# adc14 register map
Vendor: Texas Instruments
Peripheral module from a debugger description file (folder MSP432).
Registers are 32-bit, read-write, no defined reset value unless marked. A register's access mark holds for its fields unless they carry their own. Offsets are as the file gives them; lines under a group give offsets from that group; [hi:lo] are bit positions; {n}, {i} and the like mark numbered series; 'fields as' and 'values as' point back to an identical list; <NAME> marks a mode.

## ADC14
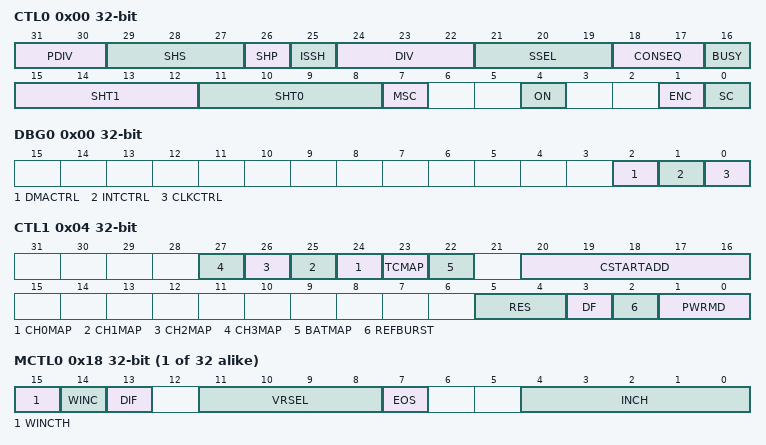
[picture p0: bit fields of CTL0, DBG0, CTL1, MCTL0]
0x00 CTL0 — Control 0 Register
  [31:30] PDIV — ADC14 predivider
    0=PDIV__0 (Predivide by 1); 1=PDIV__1 (Predivide by 4); 2=PDIV__2 (Predivide by 32); 3=PDIV__3 (Predivide by 64)
  [29:27] SHS — ADC14 sample-and-hold source select
    0=SHS__0 (ADC14SC bit); {v}=SHS__{v} (See device-specific data sheet for source) (v=1..7)
  [26] SHP — ADC14 sample-and-hold pulse-mode select
    0=SHP__0 (SAMPCON signal is sourced from the sample-input signal); 1=SHP__1 (SAMPCON signal is sourced from the sampling timer)
  [25] ISSH — ADC14 invert signal sample-and-hold
    0=ISSH__0 (The sample-input signal is not inverted); 1=ISSH__1 (The sample-input signal is inverted)
  [24:22] DIV — ADC14 clock divider. Can be modified only when ADC14ENC = 0.
    {v}=DIV__{v} (/{v+1}) (v=0..7)
  [21:19] SSEL — ADC14 clock source select
    0=SSEL__0 (MODCLK); 1=SSEL__1 (SYSCLK); 2=SSEL__2 (ACLK); 3=SSEL__3 (MCLK); 4=SSEL__4 (SMCLK); 5=SSEL__5 (HSMCLK)
  [18:17] CONSEQ — ADC14 conversion sequence mode select
    0=CONSEQ__0 (Single-channel, single-conversion); 1=CONSEQ__1 (Sequence-of-channels); 2=CONSEQ__2 (Repeat-single-channel); 3=CONSEQ__3 (Repeat-sequence-of-channels)
  [16] BUSY — ADC14 busy
    0=BUSY__0 (No operation is active); 1=BUSY__1 (A sequence, sample, or conversion is active)
  [15:12] SHT1 — ADC14 sample-and-hold time
    0=SHT1__0 (4); 1=SHT1__1 (8); 2=SHT1__2 (16); 3=SHT1__3 (32); 4=SHT1__4 (64); 5=SHT1__5 (96); 6=SHT1__6 (128); 7=SHT1__7 (192)
  [11:8] SHT0 — ADC14 sample-and-hold time
    0=SHT0__0 (4); 1=SHT0__1 (8); 2=SHT0__2 (16); 3=SHT0__3 (32); 4=SHT0__4 (64); 5=SHT0__5 (96); 6=SHT0__6 (128); 7=SHT0__7 (192)
  [7] MSC — ADC14 multiple sample and conversion
    0=MSC__0 (The sampling timer requires a rising edge of the SHI signal to); 1=MSC__1 (The first rising edge of the SHI signal triggers the sampling t)
  [4] ON — ADC14 on
    0=ON__0 (ADC14 off); 1=ON__1 (ADC14 on)
  [1] ENC — ADC14 enable conversion
    0=ENC__0 (ADC14 disabled); 1=ENC__1 (ADC14 enabled)
  [0] SC — ADC14 start conversion
    0=SC__0 (No sample-and-conversion-start); 1=SC__1 (Start sample-and-conversion)
0x00 DBG0 — Debug Register
  [2] DMACTRL — DMA control during debug.
  [1] INTCTRL — Interrupt control during debug.
  [0] CLKCTRL — Clock control during debug.
0x00 DSCR0 — Descriptor Register
  [7:0] MODREVNO — Module revision number.
0x04 CTL1 — Control 1 Register
  [n+24] CH{n}MAP (n=0..3) — Controls internal channel {n} selection to ADC input channel MAX-{n+2}
    0=CH{n}MAP__0 (ADC input channel internal {n} is not selected); 1=CH{n}MAP__1 (ADC input channel internal {n} is selected for ADC input channel)
  [23] TCMAP — Controls temperature sensor ADC input channel selection
    0=TCMAP__0 (ADC internal temperature sensor channel is not selected for ADC); 1=TCMAP__1 (ADC internal temperature sensor channel is selected for ADC inp)
  [22] BATMAP — Controls 1/2 AVCC ADC input channel selection.
    0=BATMAP__0 (ADC internal 1/2 x AVCC channel is not selected for ADC); 1=BATMAP__1 (ADC internal 1/2 x AVCC channel is selected for ADC input chann)
  [20:16] CSTARTADD — ADC14 conversion start address
  [5:4] RES — ADC14 resolution
    0=RES__0 (8 bit (9 clock cycle conversion time)); 1=RES__1 (10 bit (11 clock cycle conversion time)); 2=RES__2 (12 bit (14 clock cycle conversion time)); 3=RES__3 (14 bit (16 clock cycle conversion time))
  [3] DF — ADC14 data read-back format
    0=DF__0 (Binary unsigned); 1=DF__1 (Signed binary (2s complement), left aligned)
  [2] REFBURST — ADC reference buffer burst
    0=REFBURST__0 (ADC reference buffer on continuously); 1=REFBURST__1 (ADC reference buffer on only during sample-and-conversion)
  [1:0] PWRMD — ADC power modes
    0=PWRMD__0 (Regular power mode for use with any resolution setting); 2=PWRMD__2 (Low-power mode for 12-bit, 10-bit, and 8-bit resolution setting)
0x08 LO0 — Window Comparator Low Threshold 0 Register
  [15:0] LO0 — Low threshold 0
0x0C HI0 — Window Comparator High Threshold 0 Register
  [15:0] HI0 — High threshold 0
0x10 LO1 — Window Comparator Low Threshold 1 Register
  [15:0] LO1 — Low threshold 1
0x14 HI1 — Window Comparator High Threshold 1 Register
  [15:0] HI1 — High threshold 1
{0x18+4i} MCTL{i} (i=0..31) — Conversion Memory Control Register
  [15] WINCTH — Window comparator threshold register selection
    0=WINCTH__0 (Use window comparator thresholds 0, ADC14LO0 and ADC14HI0); 1=WINCTH__1 (Use window comparator thresholds 1, ADC14LO1 and ADC14HI1)
  [14] WINC — Comparator window enable
    0=WINC__0 (Comparator window disabled); 1=WINC__1 (Comparator window enabled)
  [13] DIF — Differential mode. Can be modified only when ADC14ENC = 0.
    0=DIF__0 (Single-ended mode enabled); 1=DIF__1 (Differential mode enabled)
  [11:8] VRSEL — Selects combinations of V(R+) and V(R-) sources as well as the
    0=VRSEL__0 (V(R+) = AVCC, V(R-) = AVSS); 1=VRSEL__1 (V(R+) = VREF buffered, V(R-) = AVSS); 14=VRSEL__20 (V(R+) = VeREF+, V(R-) = VeREF-); 15=VRSEL__21 (V(R+) = VeREF+ buffered, V(R-) = VeREF)
  [7] EOS — End of sequence
    0=EOS__0 (Not end of sequence); 1=EOS__1 (End of sequence)
  [4:0] INCH — Input channel select
    0=INCH__0 (If ADC14DIF = 0: A0; If ADC14DIF = 1: Ain+ = A0, Ain- = A1); 1=INCH__1 (If ADC14DIF = 0: A1; If ADC14DIF = 1: Ain+ = A0, Ain- = A1); 2=INCH__2 (If ADC14DIF = 0: A2; If ADC14DIF = 1: Ain+ = A2, Ain- = A3); 3=INCH__3 (If ADC14DIF = 0: A3; If ADC14DIF = 1: Ain+ = A2, Ain- = A3); 4=INCH__4 (If ADC14DIF = 0: A4; If ADC14DIF = 1: Ain+ = A4, Ain- = A5); 5=INCH__5 (If ADC14DIF = 0: A5; If ADC14DIF = 1: Ain+ = A4, Ain- = A5); 6=INCH__6 (If ADC14DIF = 0: A6; If ADC14DIF = 1: Ain+ = A6, Ain- = A7); 7=INCH__7 (If ADC14DIF = 0: A7; If ADC14DIF = 1: Ain+ = A6, Ain- = A7); 8=INCH__8 (If ADC14DIF = 0: A8; If ADC14DIF = 1: Ain+ = A8, Ain- = A9); 9=INCH__9 (If ADC14DIF = 0: A9; If ADC14DIF = 1: Ain+ = A8, Ain- = A9); 10=INCH__16 (If ADC14DIF = 0: A10; If ADC14DIF = 1: Ain+ = A10, Ain- = A11); 11=INCH__17 (If ADC14DIF = 0: A11; If ADC14DIF = 1: Ain+ = A10, Ain- = A11); 12=INCH__18 (If ADC14DIF = 0: A12; If ADC14DIF = 1: Ain+ = A12, Ain- = A13); 13=INCH__19 (If ADC14DIF = 0: A13; If ADC14DIF = 1: Ain+ = A12, Ain- = A13); 14=INCH__20 (If ADC14DIF = 0: A14; If ADC14DIF = 1: Ain+ = A14, Ain- = A15); 15=INCH__21 (If ADC14DIF = 0: A15; If ADC14DIF = 1: Ain+ = A14, Ain- = A15); 16=INCH__22 (If ADC14DIF = 0: A16; If ADC14DIF = 1: Ain+ = A16, Ain- = A17); 17=INCH__23 (If ADC14DIF = 0: A17; If ADC14DIF = 1: Ain+ = A16, Ain- = A17); 18=INCH__24 (If ADC14DIF = 0: A18; If ADC14DIF = 1: Ain+ = A18, Ain- = A19); 19=INCH__25 (If ADC14DIF = 0: A19; If ADC14DIF = 1: Ain+ = A18, Ain- = A19); 20=INCH__32 (If ADC14DIF = 0: A20; If ADC14DIF = 1: Ain+ = A20, Ain- = A21); 21=INCH__33 (If ADC14DIF = 0: A21; If ADC14DIF = 1: Ain+ = A20, Ain- = A21); 22=INCH__34 (If ADC14DIF = 0: A22; If ADC14DIF = 1: Ain+ = A22, Ain- = A23); 23=INCH__35 (If ADC14DIF = 0: A23; If ADC14DIF = 1: Ain+ = A22, Ain- = A23); 24=INCH__36 (If ADC14DIF = 0: A24; If ADC14DIF = 1: Ain+ = A24, Ain- = A25); 25=INCH__37 (If ADC14DIF = 0: A25; If ADC14DIF = 1: Ain+ = A24, Ain- = A25); 26=INCH__38 (If ADC14DIF = 0: A26; If ADC14DIF = 1: Ain+ = A26, Ain- = A27); 27=INCH__39 (If ADC14DIF = 0: A27; If ADC14DIF = 1: Ain+ = A26, Ain- = A27); 28=INCH__40 (If ADC14DIF = 0: A28; If ADC14DIF = 1: Ain+ = A28, Ain- = A29); 29=INCH__41 (If ADC14DIF = 0: A29; If ADC14DIF = 1: Ain+ = A28, Ain- = A29); 30=INCH__48 (If ADC14DIF = 0: A30; If ADC14DIF = 1: Ain+ = A30, Ain- = A31); 31=INCH__49 (If ADC14DIF = 0: A31; If ADC14DIF = 1: Ain+ = A30, Ain- = A31)
{0x98+4i} MEM{i} (i=0..31) — Conversion Memory Register
  [15:0] CONVRES — If ADC14DF = 0, unsigned binary: The 14-bit conversion results
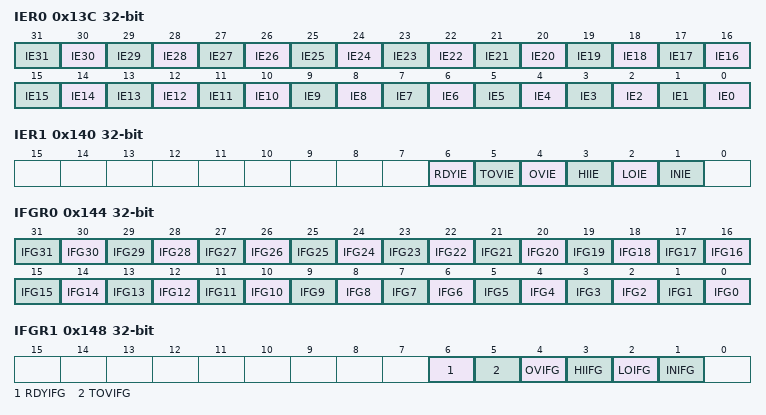
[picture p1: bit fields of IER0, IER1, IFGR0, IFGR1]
0x13C IER0 — Interrupt Enable 0 Register
  [n] IE{n} (n=0..31) — Interrupt enable
    0=IE{n}__0 (Interrupt disabled); 1=IE{n}__1 (Interrupt enabled)
0x140 IER1 — Interrupt Enable 1 Register
  [6] RDYIE — ADC14 local buffered reference ready interrupt enable.
    0=RDYIE__0 (Interrupt disabled); 1=RDYIE__1 (Interrupt enabled)
  [5] TOVIE — ADC14 conversion-time-overflow interrupt enable.
    0=TOVIE__0 (Interrupt disabled); 1=TOVIE__1 (Interrupt enabled)
  [4] OVIE — ADC14MEMx overflow-interrupt enable.
    0=OVIE__0 (Interrupt disabled); 1=OVIE__1 (Interrupt enabled)
  [3] HIIE — Interrupt enable for the exceeding the upper limit interrupt of
    0=HIIE__0 (Interrupt disabled); 1=HIIE__1 (Interrupt enabled)
  [2] LOIE — Interrupt enable for the falling short of the lower limit inter
    0=LOIE__0 (Interrupt disabled); 1=LOIE__1 (Interrupt enabled)
  [1] INIE — Interrupt enable for the ADC14MEMx result register being greate
    0=INIE__0 (Interrupt disabled); 1=INIE__1 (Interrupt enabled)
0x144 IFGR0 — Interrupt Flag 0 Register
  [n] IFG{n} (n=0..31) — ADC14MEM{n} interrupt flag
    0=IFG{n}__0 (No interrupt pending); 1=IFG{n}__1 (Interrupt pending)
0x148 IFGR1 — Interrupt Flag 1 Register
  [6] RDYIFG — ADC14 local buffered reference ready interrupt flag
    0=RDYIFG__0 (No interrupt pending); 1=RDYIFG__1 (Interrupt pending)
  [5] TOVIFG — ADC14 conversion time overflow interrupt flag
    0=TOVIFG__0 (No interrupt pending); 1=TOVIFG__1 (Interrupt pending)
  [4] OVIFG — ADC14MEMx overflow interrupt flag
    0=OVIFG__0 (No interrupt pending); 1=OVIFG__1 (Interrupt pending)
  [3] HIIFG — Interrupt flag for exceeding the upper limit interrupt of the w
    0=HIIFG__0 (No interrupt pending); 1=HIIFG__1 (Interrupt pending)
  [2] LOIFG — Interrupt flag for falling short of the lower limit interrupt o
    0=LOIFG__0 (No interrupt pending); 1=LOIFG__1 (Interrupt pending)
  [1] INIFG — Interrupt flag for the ADC14MEMx result register being greater
    0=INIFG__0 (No interrupt pending); 1=INIFG__1 (Interrupt pending)
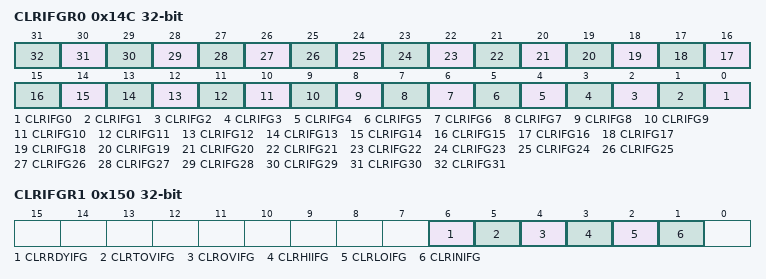
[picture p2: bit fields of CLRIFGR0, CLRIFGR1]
0x14C CLRIFGR0 — Clear Interrupt Flag 0 Register
  [n] CLRIFG{n} (n=0..31) — clear ADC14IFG{n}
    0=CLRIFG{n}__0 (no effect); 1=CLRIFG{n}__1 (clear pending interrupt flag)
0x150 CLRIFGR1 — Clear Interrupt Flag 1 Register
  [6] CLRRDYIFG — clear ADC14RDYIFG
    0=CLRRDYIFG__0 (no effect); 1=CLRRDYIFG__1 (clear pending interrupt flag)
  [5] CLRTOVIFG — clear ADC14TOVIFG
    0=CLRTOVIFG__0 (no effect); 1=CLRTOVIFG__1 (clear pending interrupt flag)
  [4] CLROVIFG — clear ADC14OVIFG
    0=CLROVIFG__0 (no effect); 1=CLROVIFG__1 (clear pending interrupt flag)
  [3] CLRHIIFG — clear ADC14HIIFG
    0=CLRHIIFG__0 (no effect); 1=CLRHIIFG__1 (clear pending interrupt flag)
  [2] CLRLOIFG — clear ADC14LOIFG
    0=CLRLOIFG__0 (no effect); 1=CLRLOIFG__1 (clear pending interrupt flag)
  [1] CLRINIFG — clear ADC14INIFG
    0=CLRINIFG__0 (no effect); 1=CLRINIFG__1 (clear pending interrupt flag)
0x154 IV — Interrupt Vector Register
  [31:0] IV — ADC14 interrupt vector value
    0=IV__0 (No interrupt pending); 2=IV__2 (Interrupt Source: ADC14MEMx overflow; Interrupt Flag: ADC14OVIF); 4=IV__4 (Interrupt Source: Conversion time overflow; Interrupt Flag: ADC); 6=IV__6 (Interrupt Source: ADC14 window high interrupt flag; Interrupt F); 8=IV__8 (Interrupt Source: ADC14 window low interrupt flag; Interrupt Fl); 10=IV__16 (Interrupt Source: ADC14 in-window interrupt flag; Interrupt Fla); 12=IV__18 (Interrupt Source: ADC14MEM0 interrupt flag; Interrupt Flag: ADC); 14=IV__20; 16=IV__22 (Interrupt Source: ADC14MEM2 interrupt flag; Interrupt Flag: ADC); 18=IV__24 (Interrupt Source: ADC14MEM3 interrupt flag; Interrupt Flag: ADC); 20=IV__32 (Interrupt Source: ADC14MEM4 interrupt flag; Interrupt Flag: ADC); 22=IV__34 (Interrupt Source: ADC14MEM5 interrupt flag; Interrupt Flag: ADC); 24=IV__36 (Interrupt Source: ADC14MEM6 interrupt flag; Interrupt Flag: ADC); 26=IV__38 (Interrupt Source: ADC14MEM7 interrupt flag; Interrupt Flag: ADC); 28=IV__40 (Interrupt Source: ADC14MEM8 interrupt flag; Interrupt Flag: ADC); 30=IV__48 (Interrupt Source: ADC14MEM9 interrupt flag; Interrupt Flag: ADC); 32=IV__50 (Interrupt Source: ADC14MEM10 interrupt flag; Interrupt Flag: AD); 34=IV__52 (Interrupt Source: ADC14MEM11 interrupt flag; Interrupt Flag: AD); 36=IV__54 (Interrupt Source: ADC14MEM12 interrupt flag; Interrupt Flag: AD); 38=IV__56 (Interrupt Source: ADC14MEM13 interrupt flag; Interrupt Flag: AD); 40=IV__64 (Interrupt Source: ADC14MEM14 interrupt flag; Interrupt Flag: AD); 42=IV__66 (Interrupt Source: ADC14MEM15 interrupt flag; Interrupt Flag: AD); 44=IV__68 (Interrupt Source: ADC14MEM16 interrupt flag; Interrupt Flag: AD); 46=IV__70 (Interrupt Source: ADC14MEM17 interrupt flag; Interrupt Flag: AD); 48=IV__72 (Interrupt Source: ADC14MEM18 interrupt flag; Interrupt Flag: AD); 50=IV__80 (Interrupt Source: ADC14MEM19 interrupt flag; Interrupt Flag: AD); 52=IV__82 (Interrupt Source: ADC14MEM20 interrupt flag; Interrupt Flag: AD); 54=IV__84 (Interrupt Source: ADC14MEM22 interrupt flag; Interrupt Flag: AD); 56=IV__86 (Interrupt Source: ADC14MEM22 interrupt flag; Interrupt Flag: AD); 58=IV__88 (Interrupt Source: ADC14MEM23 interrupt flag; Interrupt Flag: AD); 60=IV__96 (Interrupt Source: ADC14MEM24 interrupt flag; Interrupt Flag: AD); 62=IV__98 (Interrupt Source: ADC14MEM25 interrupt flag; Interrupt Flag: AD); 64=IV__100 (Interrupt Source: ADC14MEM26 interrupt flag; Interrupt Flag: AD); 66=IV__102 (Interrupt Source: ADC14MEM27 interrupt flag; Interrupt Flag: AD); 68=IV__104 (Interrupt Source: ADC14MEM28 interrupt flag; Interrupt Flag: AD); 70=IV__112 (Interrupt Source: ADC14MEM29 interrupt flag; Interrupt Flag: AD); 72=IV__114 (Interrupt Source: ADC14MEM30 interrupt flag; Interrupt Flag: AD); 74=IV__116 (Interrupt Source: ADC14MEM31 interrupt flag; Interrupt Flag: AD); 76=IV__118 (Interrupt Source: ADC14RDYIFG interrupt flag; Interrupt Flag: A)
